# MB9BF12xJ register map
File version: 1.0
Registers are 32-bit, read-write, reset 0x0 unless marked. A register's access mark holds for its fields unless they carry their own. Offsets are from the block's base; [hi:lo] are bit positions; {n}, {i} and the like mark numbered series.

## ADC0 — peripheral ADC0
Base 0x40027000
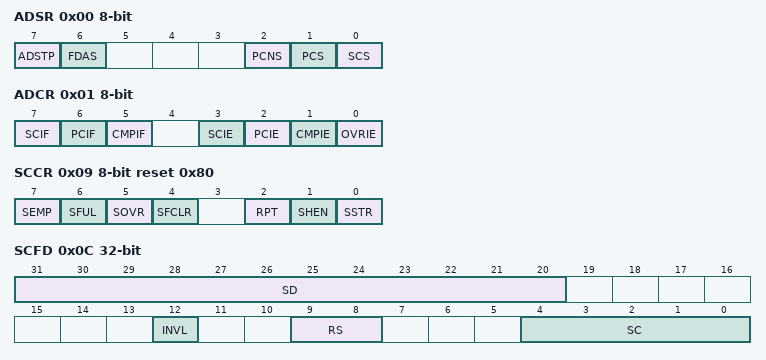
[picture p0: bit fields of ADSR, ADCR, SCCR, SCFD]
0x00 ADSR 8-bit
  [7] ADSTP, [6] FDAS, [2] PCNS, [1] PCS, [0] SCS
0x01 ADCR 8-bit
  [7] SCIF, [6] PCIF, [5] CMPIF, [3] SCIE, [2] PCIE, [1] CMPIE, [0] OVRIE
0x08 SFNS 8-bit
  [3:0] SFS
0x09 SCCR 8-bit reset 0x80
  [7] SEMP ro, [6] SFUL ro, [5] SOVR, [4] SFCLR, [2] RPT, [1] SHEN, [0] SSTR
0x0C SCFD ro
  [31:20] SD, [12] INVL, [9:8] RS, [4:0] SC
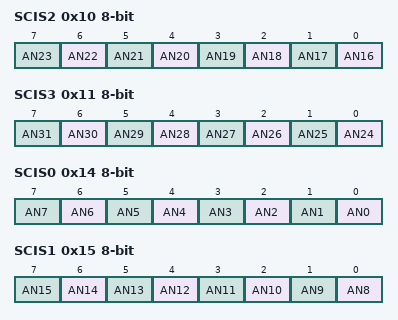
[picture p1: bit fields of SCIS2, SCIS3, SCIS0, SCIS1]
0x10 SCIS2 8-bit
  [n-16] AN{n} (n=16..23)
0x11 SCIS3 8-bit
  [n-24] AN{n} (n=24..31)
0x14 SCIS0 8-bit
  [n] AN{n} (n=0..7)
0x15 SCIS1 8-bit
  [n-8] AN{n} (n=8..15)
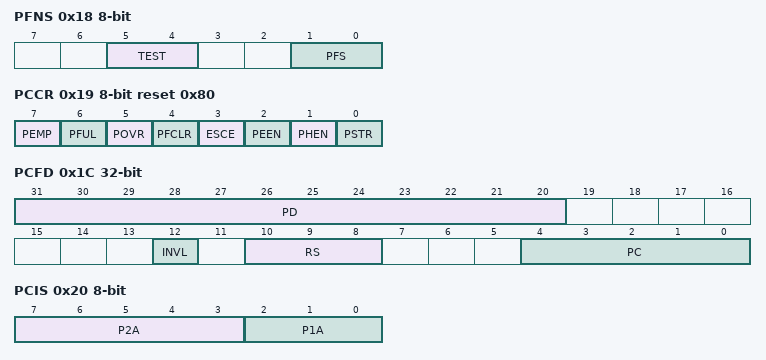
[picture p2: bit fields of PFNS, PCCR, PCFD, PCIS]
0x18 PFNS 8-bit
  [5:4] TEST ro, [1:0] PFS
0x19 PCCR 8-bit reset 0x80
  [7] PEMP ro, [6] PFUL ro, [5] POVR, [4] PFCLR, [3] ESCE, [2] PEEN, [1] PHEN, [0] PSTR
0x1C PCFD ro
  [31:20] PD, [12] INVL, [10:8] RS, [4:0] PC
0x20 PCIS 8-bit
  [7:3] P2A, [2:0] P1A
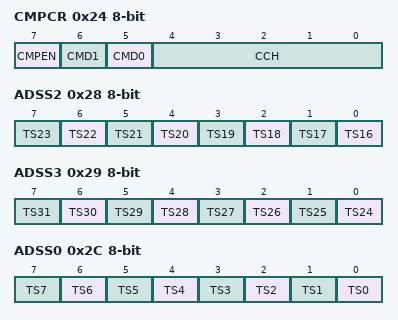
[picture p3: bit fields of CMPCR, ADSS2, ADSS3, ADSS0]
0x24 CMPCR 8-bit
  [7] CMPEN, [6] CMD1, [5] CMD0, [4:0] CCH
0x26 CMPD 16-bit
  [15:6] CMAD
0x28 ADSS2 8-bit
  [n-16] TS{n} (n=16..23)
0x29 ADSS3 8-bit
  [n-24] TS{n} (n=24..31)
0x2C ADSS0 8-bit
  [n] TS{n} (n=0..7)
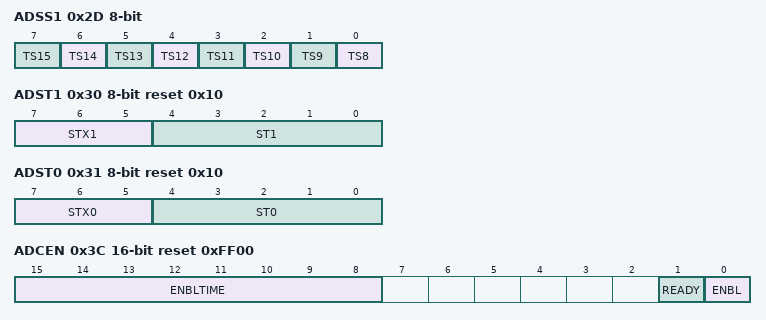
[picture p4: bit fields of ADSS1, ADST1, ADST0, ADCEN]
0x2D ADSS1 8-bit
  [n-8] TS{n} (n=8..15)
0x30 ADST1 8-bit reset 0x10
  [7:5] STX1, [4:0] ST1
0x31 ADST0 8-bit reset 0x10
  [7:5] STX0, [4:0] ST0
0x34 ADCT 8-bit reset 0x7 (reset mask 0x7)
  [7:0] CT
0x38 PRTSL 8-bit
  [3:0] PRTSL
0x39 SCTSL 8-bit
  [3:0] SCTSL
0x3C ADCEN 16-bit reset 0xFF00
  [15:8] ENBLTIME, [1] READY ro, [0] ENBL

## EXTI — peripheral EXTI
Base 0x40030000
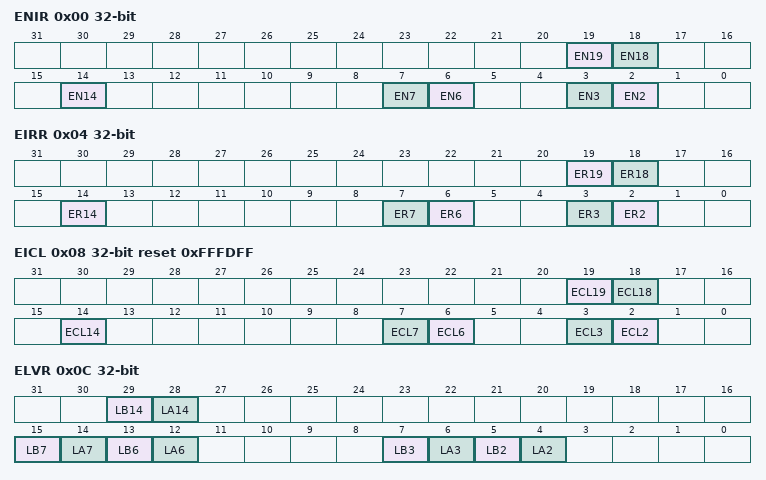
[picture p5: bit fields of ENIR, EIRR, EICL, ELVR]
0x00 ENIR
  [19] EN19, [18] EN18, [14] EN14, [7] EN7, [6] EN6, [3] EN3, [2] EN2
0x04 EIRR ro reset not defined
  [19] ER19 rw, [18] ER18 rw, [14] ER14, [7] ER7, [6] ER6, [3] ER3, [2] ER2
0x08 EICL reset 0xFFFDFF
  [19] ECL19, [18] ECL18, [14] ECL14, [7] ECL7, [6] ECL6, [3] ECL3, [2] ECL2
0x0C ELVR
  [29] LB14, [28] LA14, [15] LB7, [14] LA7, [13] LB6, [12] LA6, [7] LB3, [6] LA3, [5] LB2, [4] LA2
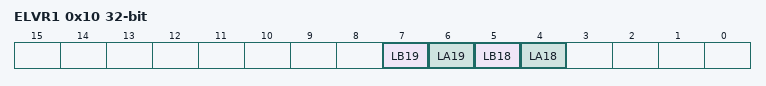
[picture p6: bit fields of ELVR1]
0x10 ELVR1
  [7] LB19, [6] LA19, [5] LB18, [4] LA18
0x14 NMIRR 8-bit ro
  [0] NR
0x18 NMICL 8-bit reset 0x1
  [0] NCL

## INTREQ — peripheral INTREQ
Base 0x40031000
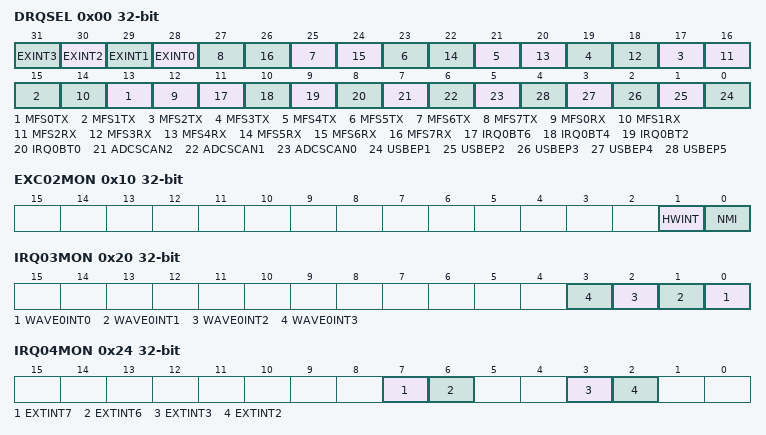
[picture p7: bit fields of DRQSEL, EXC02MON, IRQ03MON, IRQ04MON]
0x00 DRQSEL
  [n+28] EXINT{n} (n=0..3), [2n+13] MFS{n}TX (n=0..7), [2n+12] MFS{n}RX (n=0..7), [11] IRQ0BT6, [10] IRQ0BT4, [9] IRQ0BT2, [8] IRQ0BT0, [7] ADCSCAN2, [6] ADCSCAN1, [5] ADCSCAN0, [n-1] USBEP{n} (n=1..5)
0x0B ODDPKS 8-bit reset not defined
0x0C IRQCMODE
  [0] IRQCMODE
0x10 EXC02MON ro
  [1] HWINT, [0] NMI
0x14 IRQ00MON ro
  [0] FCSINT
0x18 IRQ01MON ro
  [0] SWWDTINT
0x1C IRQ02MON ro
  [0] LVDINT
0x20 IRQ03MON ro
  [n] WAVE0INT{n} (n=0..3)
0x24 IRQ04MON ro
  [7] EXTINT7, [6] EXTINT6, [3] EXTINT3, [2] EXTINT2
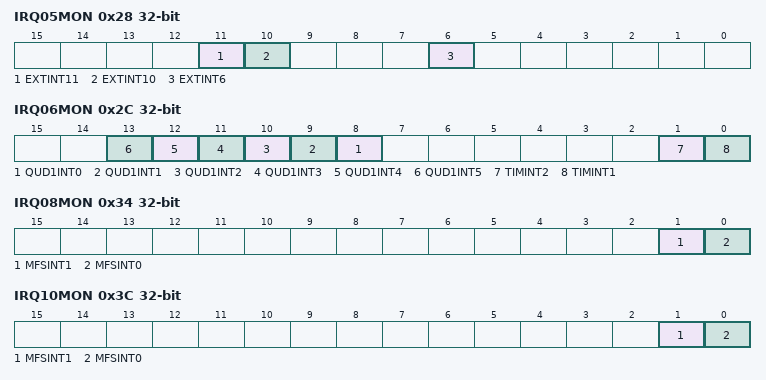
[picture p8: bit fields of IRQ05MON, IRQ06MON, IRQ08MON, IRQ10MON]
0x28 IRQ05MON ro
  [11] EXTINT11, [10] EXTINT10, [6] EXTINT6
0x2C IRQ06MON ro
  [n+8] QUD1INT{n} (n=0..5), [1] TIMINT2, [0] TIMINT1
0x30 IRQ07MON ro
  [0] MFSINT0
0x34 IRQ08MON ro
  [1] MFSINT1, [0] MFSINT0
0x38 IRQ09MON ro
  [0] MFSINT0
0x3C IRQ10MON ro
  [1] MFSINT1, [0] MFSINT0
0x40 IRQ11MON ro
  [0] MFSINT0
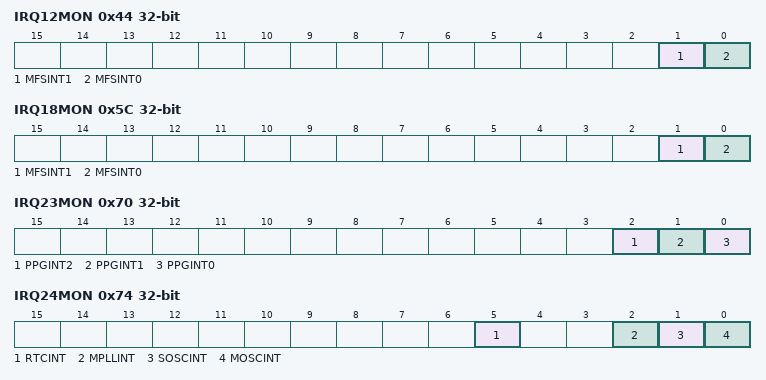
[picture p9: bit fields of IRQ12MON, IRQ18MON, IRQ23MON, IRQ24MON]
0x44 IRQ12MON ro
  [1] MFSINT1, [0] MFSINT0
{0x14+4i} IRQ{i}MON ro reset not defined (i=13..16)
0x58 IRQ17MON ro
  [0] MFSINT0
0x5C IRQ18MON ro
  [1] MFSINT1, [0] MFSINT0
{0x14+4i} IRQ{i}MON ro reset not defined (i=19..22)
0x70 IRQ23MON ro
  [2] PPGINT2, [1] PPGINT1, [0] PPGINT0
0x74 IRQ24MON ro
  [5] RTCINT, [2] MPLLINT, [1] SOSCINT, [0] MOSCINT
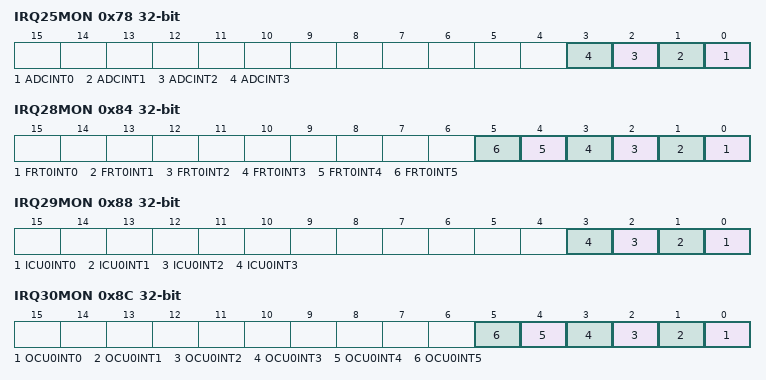
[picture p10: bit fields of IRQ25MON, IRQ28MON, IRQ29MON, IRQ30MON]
0x78 IRQ25MON ro
  [n] ADCINT{n} (n=0..3)
0x7C IRQ26MON ro reset not defined
0x80 IRQ27MON ro reset not defined
0x84 IRQ28MON ro
  [n] FRT0INT{n} (n=0..5)
0x88 IRQ29MON ro
  [n] ICU0INT{n} (n=0..3)
0x8C IRQ30MON ro reset not defined
  [n] OCU0INT{n} (n=0..5)
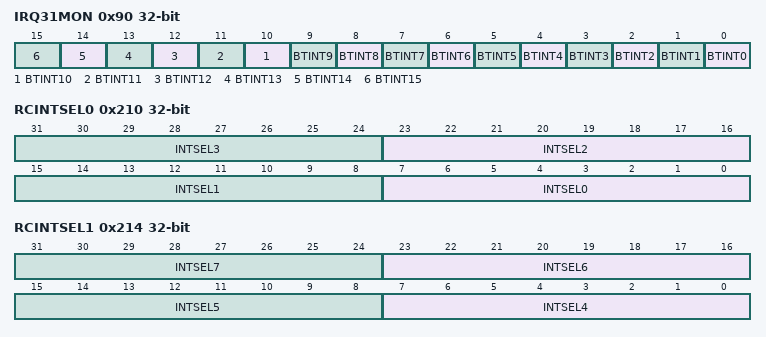
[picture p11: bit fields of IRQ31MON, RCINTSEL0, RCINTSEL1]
0x90 IRQ31MON ro
  [n] BTINT{n} (n=0..15)
{0x14+4i} IRQ{i}MON ro reset not defined (i=32..37)
{0x14+4i} IRQ{i}MON ro (i=38..41)
  [0] DMAINT
{0x14+4i} IRQ{i}MON ro reset not defined (i=42..46)
0xD0 IRQ47MON ro
  [11] FLASHINT
0x210 RCINTSEL0
  [8n+7:8n] INTSEL{n} (n=0..3)
0x214 RCINTSEL1
  [8n-25:8n-32] INTSEL{n} (n=4..7)
